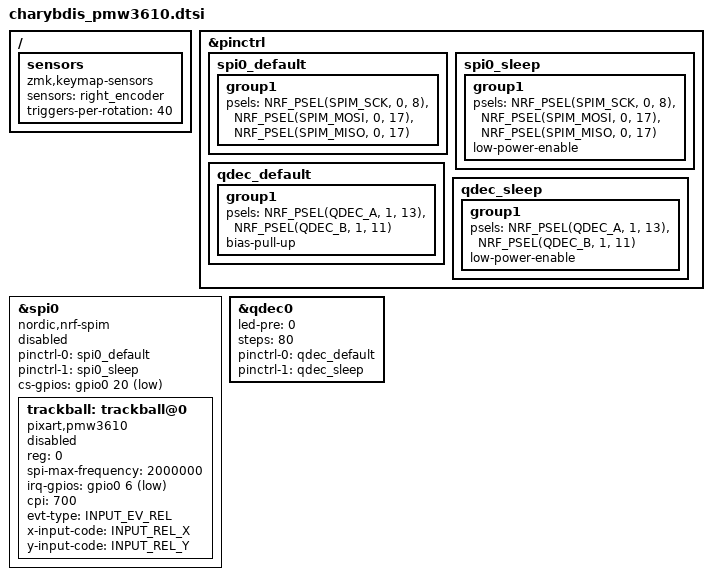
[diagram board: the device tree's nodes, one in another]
#define INPUT_EV_KEY 0x01               /**< Key event */
#define INPUT_EV_REL 0x02               /**< Relative coordinate event */
#define INPUT_EV_ABS 0x03               /**< Absolute coordinate event */
#define INPUT_EV_MSC 0x04               /**< Miscellaneous event */
#define INPUT_EV_VENDOR_START 0xf0      /**< Vendor specific event start */
#define INPUT_EV_VENDOR_STOP 0xff       /**< Vendor specific event stop */

#define INPUT_REL_X 0x00                /**< Relative X coordinate */
#define INPUT_REL_Y 0x01                /**< Relative Y coordinate */
#define INPUT_REL_WHEEL 0x08            /**< Relative wheel coordinate */
#define INPUT_REL_HWHEEL 0x06           /**< Relative horizontal wheel coordinate */
#define INPUT_REL_MISC 0x09             /**< Relative misc coordinate */

&pinctrl {
    spi0_default: spi0_default {
        group1 {
            psels = <NRF_PSEL(SPIM_SCK, 0, 8)>,
                <NRF_PSEL(SPIM_MOSI, 0, 17)>,
                <NRF_PSEL(SPIM_MISO, 0, 17)>;
        };
    };

    spi0_sleep: spi0_sleep {
        group1 {
            psels = <NRF_PSEL(SPIM_SCK, 0, 8)>,
                <NRF_PSEL(SPIM_MOSI, 0, 17)>,
                <NRF_PSEL(SPIM_MISO, 0, 17)>;
            low-power-enable;
        };
    };

    qdec_default: qdec_default {
        group1 {
            psels = <NRF_PSEL(QDEC_A, 1, 13)>,
                    <NRF_PSEL(QDEC_B, 1, 11)>;
            bias-pull-up;
        };
    };

    qdec_sleep: qdec_sleep {
        group1 {
            psels = <NRF_PSEL(QDEC_A, 1, 13)>,
                    <NRF_PSEL(QDEC_B, 1, 11)>;
            low-power-enable;
        };
    };


};

&spi0 {
    status = "disabled";
    compatible = "nordic,nrf-spim";
    pinctrl-0 = <&spi0_default>;
    pinctrl-1 = <&spi0_sleep>;
    pinctrl-names = "default", "sleep";
    cs-gpios = <&gpio0 20 GPIO_ACTIVE_LOW>;

    trackball: trackball@0 {
        status = "disabled";
        compatible = "pixart,pmw3610";
        reg = <0>;
        spi-max-frequency = <2000000>;
        irq-gpios = <&gpio0 6 (GPIO_ACTIVE_LOW | GPIO_PULL_UP)>;
        cpi = <700>;
        evt-type = <INPUT_EV_REL>;
        x-input-code = <INPUT_REL_X>;
        y-input-code = <INPUT_REL_Y>;
    };
};

// Set up the QDEC hardware based driver and give it the same label as the deleted node.
right_encoder: &qdec0 {
    status = "okay";
    led-pre = <0>;
    steps = <80>;
    pinctrl-0 = <&qdec_default>;
    pinctrl-1 = <&qdec_sleep>;
    pinctrl-names = "default","sleep";
};

/ {
	sensors {
		compatible = "zmk,keymap-sensors";
		sensors = <&right_encoder>;
        triggers-per-rotation = <40>;
	};
};

